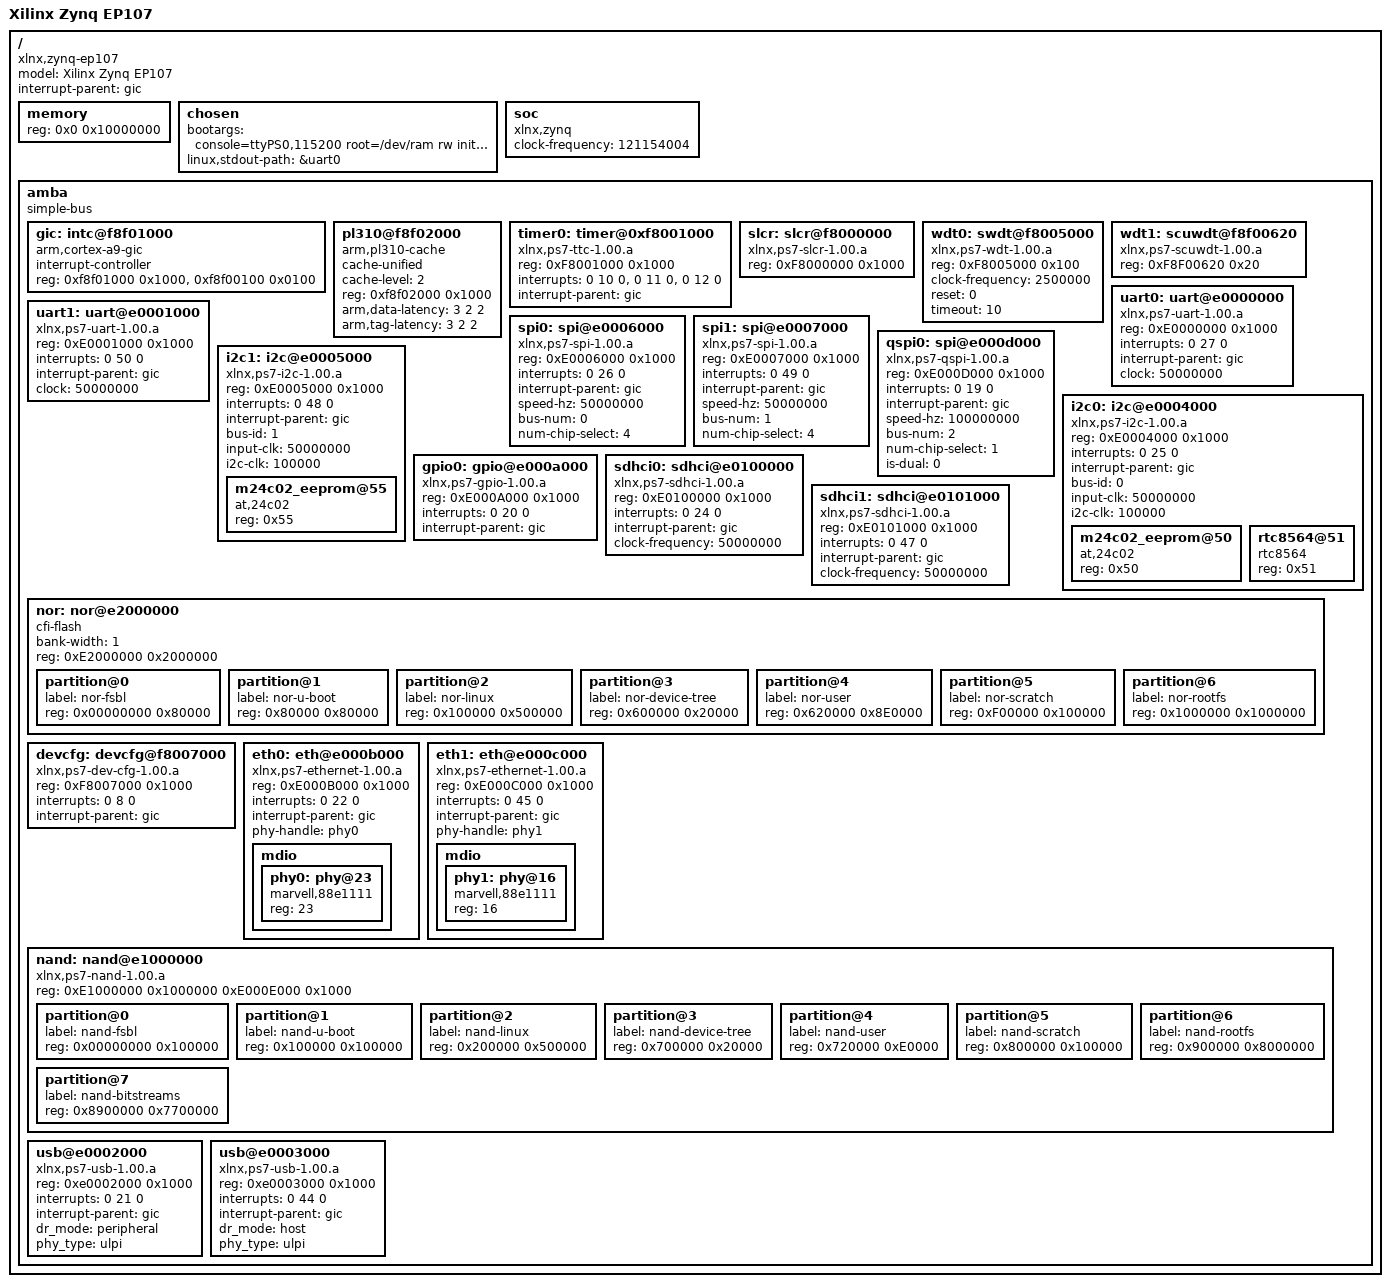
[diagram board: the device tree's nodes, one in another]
/*
 *  Copyright (C) 2011 Xilinx
 *
 * This software is licensed under the terms of the GNU General Public
 * License version 2, as published by the Free Software Foundation, and
 * may be copied, distributed, and modified under those terms.
 *
 * This program is distributed in the hope that it will be useful,
 * but WITHOUT ANY WARRANTY; without even the implied warranty of
 * MERCHANTABILITY or FITNESS FOR A PARTICULAR PURPOSE.  See the
 * GNU General Public License for more details.
 */

/dts-v1/;
/ {
	model = "Xilinx Zynq EP107";
	compatible = "xlnx,zynq-ep107";
	#address-cells = <1>;
	#size-cells = <1>;
	interrupt-parent = <&gic>;

	memory {
		device_type = "memory";
		reg = <0x0 0x10000000>;
	};

	chosen {
		bootargs = "console=ttyPS0,115200 root=/dev/ram rw initrd=0x800000,8M earlyprintk ip=:::::eth0:dhcp";
		linux,stdout-path = &uart0;
	};

	soc {
		compatible = "xlnx,zynq";
		clock-frequency = <121154004>;
	};

	amba {
		compatible = "simple-bus";
		#address-cells = <1>;
		#size-cells = <1>;
		ranges;

		gic: intc@f8f01000 {
			interrupt-controller;
			compatible = "arm,cortex-a9-gic";
			#interrupt-cells = <3>;
			reg = < 0xf8f01000 0x1000 >,
			      < 0xf8f00100 0x0100 >;
		};

		pl310@f8f02000 {
			compatible = "arm,pl310-cache";
			cache-unified;
			cache-level = <2>;
			reg = <0xf8f02000 0x1000>;
			arm,data-latency = <3 2 2>;
			arm,tag-latency = <3 2 2>;
		};

		timer0: timer@0xf8001000 {
			compatible = "xlnx,ps7-ttc-1.00.a";
			reg = <0xF8001000 0x1000>;
			interrupts = <0 10 0>,<0 11 0>,<0 12 0>;
			interrupt-parent = <&gic>;
		};

		slcr: slcr@f8000000 {
			compatible = "xlnx,ps7-slcr-1.00.a";
			reg = <0xF8000000 0x1000>;
		};

		wdt0: swdt@f8005000 {
			device_type = "watchdog";
			compatible = "xlnx,ps7-wdt-1.00.a";
			reg = <0xF8005000 0x100>;
			clock-frequency = <2500000>;
			reset = <0>;
			timeout = <10>;
		};

		wdt1: scuwdt@f8f00620 {
			device_type = "watchdog";
			compatible = "xlnx,ps7-scuwdt-1.00.a";
			reg = <0xF8F00620 0x20>;
		};

		uart0: uart@e0000000 {
			compatible = "xlnx,ps7-uart-1.00.a";
			reg = <0xE0000000 0x1000>;
			interrupts = <0 27 0>;
			interrupt-parent = <&gic>;
			clock = <50000000>;
		};

		uart1: uart@e0001000 {
			compatible = "xlnx,ps7-uart-1.00.a";
			reg = <0xE0001000 0x1000>;
			interrupts = <0 50 0>;
			interrupt-parent = <&gic>;
			clock = <50000000>;
		};

		spi0: spi@e0006000 {
			compatible = "xlnx,ps7-spi-1.00.a";
			reg = <0xE0006000 0x1000>;
			interrupts = <0 26 0>;
			interrupt-parent = <&gic>;
			speed-hz = <50000000>;
			bus-num = <0>;
			num-chip-select = <4>;
		};

		spi1: spi@e0007000 {
			compatible = "xlnx,ps7-spi-1.00.a";
			reg = <0xE0007000 0x1000>;
			interrupts = <0 49 0>;
			interrupt-parent = <&gic>;
			speed-hz = <50000000>;
			bus-num = <1>;
			num-chip-select = <4>;
		};

		qspi0: spi@e000d000 {
			compatible = "xlnx,ps7-qspi-1.00.a";
			reg = <0xE000D000 0x1000>;
			interrupts = <0 19 0>;
			interrupt-parent = <&gic>;
			speed-hz = <100000000>;
			bus-num = <2>;
			num-chip-select = <1>;
			is-dual = <0>;
		};

		i2c0: i2c@e0004000 {
			compatible = "xlnx,ps7-i2c-1.00.a";
			reg = <0xE0004000 0x1000>;
			interrupts = <0 25 0>;
			interrupt-parent = <&gic>;
			bus-id = <0>;
			input-clk = <50000000>;
			i2c-clk = <100000>;

			#address-cells = <1>;
			#size-cells = <0>;
			m24c02_eeprom@50 {
				compatible = "at,24c02";
				reg = <0x50>;
			};

			rtc8564@51 {
				compatible = "rtc8564";
				reg = <0x51>;
			};
		};

		i2c1: i2c@e0005000 {
			compatible = "xlnx,ps7-i2c-1.00.a";
			reg = <0xE0005000 0x1000>;
			interrupts = <0 48 0>;
			interrupt-parent = <&gic>;
			bus-id = <1>;
			input-clk = <50000000>;
			i2c-clk = <100000>;

			#address-cells = <1>;
			#size-cells = <0>;
			m24c02_eeprom@55 {
				compatible = "at,24c02";
				reg = <0x55>;
			};
		};

		gpio0: gpio@e000a000 {
			compatible = "xlnx,ps7-gpio-1.00.a";
			reg = <0xE000A000 0x1000>;
			interrupts = <0 20 0>;
			interrupt-parent = <&gic>;
		};

		sdhci0: sdhci@e0100000 {
			compatible = "xlnx,ps7-sdhci-1.00.a";
			reg = <0xE0100000 0x1000>;
			interrupts = <0 24 0>;
			interrupt-parent = <&gic>;
			clock-frequency = <50000000>;
		};

		sdhci1: sdhci@e0101000 {
			compatible = "xlnx,ps7-sdhci-1.00.a";
			reg = <0xE0101000 0x1000>;
			interrupts = <0 47 0>;
			interrupt-parent = <&gic>;
			clock-frequency = <50000000>;
		};

		nor: nor@e2000000 {
			compatible = "cfi-flash";
			bank-width = <1>;
			reg = <0xE2000000 0x2000000>;		/* 32MB */
			#address-cells = <1>;
			#size-cells = <1>;
			partition@0 {
				label = "nor-fsbl";
				reg = <0x00000000 0x80000>;	/* 512K */
			};
			partition@1 {
				label = "nor-u-boot";
				reg = <0x80000 0x80000>;	/* 512K */
			};
			partition@2 {
				label = "nor-linux";
				reg = <0x100000 0x500000>;	/* 5 MB */
			};
			partition@3 {
				label = "nor-device-tree";
				reg = <0x600000 0x20000>;	/* 128K */
			};
			partition@4{
				label = "nor-user";
				reg = <0x620000 0x8E0000>;	/* 8875K */
			};
			partition@5{
				label = "nor-scratch";
				reg = <0xF00000 0x100000>;	/* 1 MB */
			};
			partition@6{
				label = "nor-rootfs";
				reg = <0x1000000 0x1000000>;	/* 16 MB */
			};
                };

		devcfg: devcfg@f8007000 {
			compatible = "xlnx,ps7-dev-cfg-1.00.a";
			reg = <0xF8007000 0x1000>;
			interrupts = <0 8 0>;
			interrupt-parent = <&gic>;
		};
		eth0: eth@e000b000 {
			compatible = "xlnx,ps7-ethernet-1.00.a";
			reg = <0xE000B000 0x1000>;
			interrupts = <0 22 0>;
			interrupt-parent = <&gic>;
			phy-handle = <&phy0>;
			#address-cells = <1>;
			#size-cells = <0>;
			mdio {
				#address-cells = <1>;
				#size-cells = <0>;
				phy0: phy@23 {
					compatible = "marvell,88e1111";
					device_type = "ethernet-phy";
					reg = <23>;
				};
			};
		};

		eth1: eth@e000c000 {
			compatible = "xlnx,ps7-ethernet-1.00.a";
			reg = <0xE000C000 0x1000>;
			interrupts = <0 45 0>;
			interrupt-parent = <&gic>;
			phy-handle = <&phy1>;
			#address-cells = <1>;
			#size-cells = <0>;
			mdio {
				#address-cells = <1>;
				#size-cells = <0>;
				phy1: phy@16 {
					compatible = "marvell,88e1111";
					device_type = "ethernet-phy";
					reg = <16>;
				};
			};
		};

		nand: nand@e1000000 {
			compatible = "xlnx,ps7-nand-1.00.a";
			reg = <0xE1000000 0x1000000 0xE000E000 0x1000>;
			#address-cells = <1>;
			#size-cells = <1>;
			partition@0 {
				label = "nand-fsbl";
				reg = <0x00000000 0x100000>;	/* 1 MB */
			};
			partition@1 {
				label = "nand-u-boot";
				reg = <0x100000 0x100000>;	/* 1 MB */
			};
			partition@2 {
				label = "nand-linux";
				reg = <0x200000 0x500000>;	/* 5 MB */
			};
			partition@3 {
				label = "nand-device-tree";
				reg = <0x700000 0x20000>;	/* 128 KB */
			};
			partition@4 {
				label = "nand-user";
				reg = <0x720000 0xE0000>;	/* 896 KB */
			};
			partition@5 {
				label = "nand-scratch";
				reg = <0x800000 0x100000>;	/* 1 MB */
			};
			partition@6 {
				label = "nand-rootfs";
				reg = <0x900000 0x8000000>;	/* 128 MB */
			};
			partition@7 {
				label = "nand-bitstreams";
				reg = <0x8900000 0x7700000>;	/* 119 MB */
			};
		};

		usb@e0002000 {
			compatible = "xlnx,ps7-usb-1.00.a";
			reg = <0xe0002000 0x1000>;
			interrupts = <0 21 0>;
			interrupt-parent = <&gic>;
			dr_mode = "peripheral";
			phy_type = "ulpi";
		};

		usb@e0003000 {
			compatible = "xlnx,ps7-usb-1.00.a";
			reg = <0xe0003000 0x1000>;
			interrupts = <0 44 0>;
			interrupt-parent = <&gic>;
			dr_mode = "host";
			phy_type = "ulpi";
		};
	};
};
